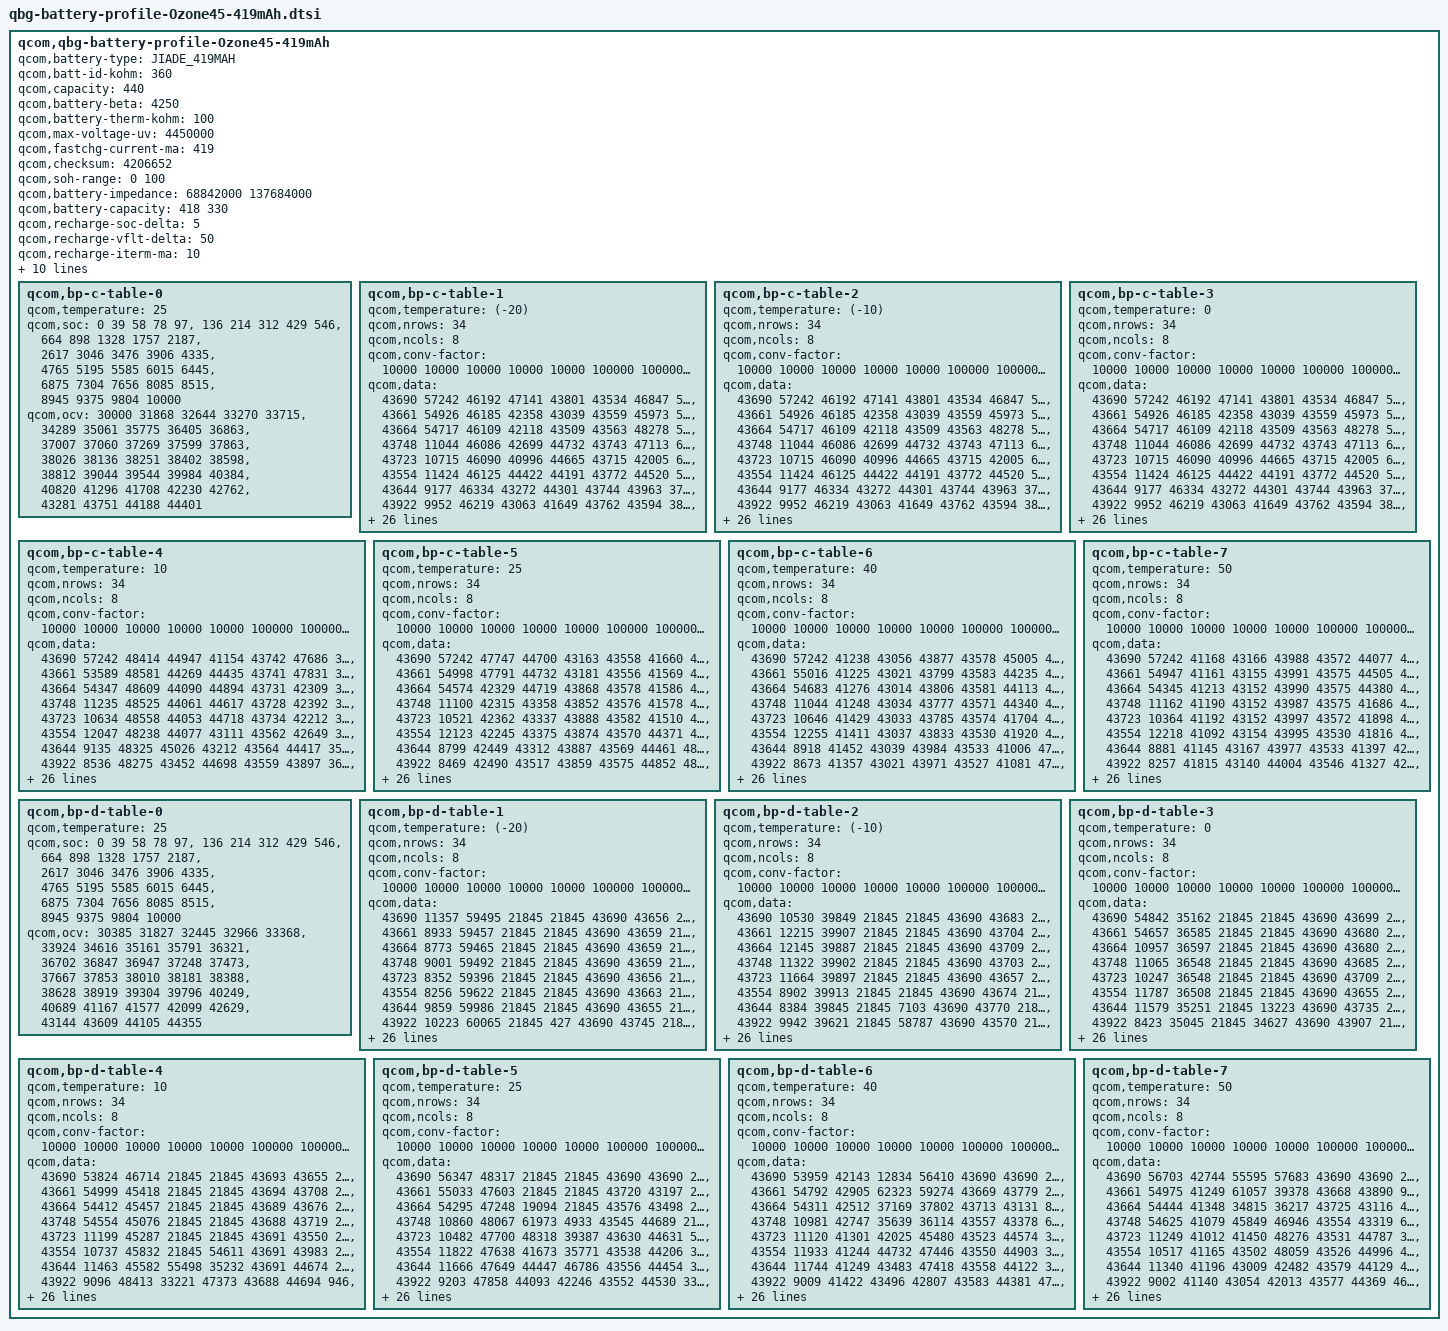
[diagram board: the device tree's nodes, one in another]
qcom,qbg-battery-profile-Ozone45-419mAh {
	qcom,battery-type = "JIADE_419MAH";
	qcom,batt-id-kohm = <360>;
	qcom,capacity = <440>;
	qcom,battery-beta = <4250>;
	qcom,battery-therm-kohm = <100>;
	qcom,max-voltage-uv = <4450000>;
	qcom,fastchg-current-ma = <419>;
	qcom,checksum = <4206652>; /*@5, 0.005V, 4% */
	qcom,soh-range = <0 100>;
	/* Nominal_Impedance in 10nohm @ SOC 50% 25C* 0:fresh cell, 1: aged cell */
	qcom,battery-impedance = <68842000 137684000>;
	/* Nominal_Capacity in mAh. 0: fresh cell, 1:aged cell */
	qcom,battery-capacity = <418 330>;
	/* SOC delta (in percent) dropped from EOC SOC to enable recharge */
	qcom,recharge-soc-delta =<5>;
	/* vfloat delta (in mV) dropped from regular vfloat in recharge */
	qcom,recharge-vflt-delta =<50>;
	/* Termination current (in mA) in recharge */
	qcom,recharge-iterm-ma = <10>;

	qcom,jeita-fcc-ranges = <0 150 84000
				151 435 419000
				436 445 400000
				446 450 84000>;

	qcom,jeita-fv-ranges = <0 150 4300000
				151 435 4450000
				436 445 4450000
				446 450 4350000>;

	/* COOL = 15 DegC, WARM = 45 DegC */
	qcom,jeita-soft-thresholds = <0x27c1 0x128c>;
	/* COLD = 0 DegC, HOT = 45.1 DegC */
	qcom,jeita-hard-thresholds = <0x3257 0x127e>;
	/* COOL = 18 DegC, WARM = 44 DegC*/
	qcom,jeita-soft-hys-thresholds = <0x256e 0x131c>;
	qcom,step-jeita-hysteresis = <5 5>;
	qcom,jeita-soft-fcc-ua = <140000 419000>;
	qcom,jeita-soft-fv-uv = <4300000 4300000>;

	qcom,bp-c-table-0 {
		qcom,temperature = <25>;
		qcom,soc = <    0    39    58    78    97>,
			<  136   214   312   429   546>,
			<  664   898  1328  1757  2187>,
			< 2617  3046  3476  3906  4335>,
			< 4765  5195  5585  6015  6445>,
			< 6875  7304  7656  8085  8515>,
			< 8945  9375  9804 10000>;
		qcom,ocv = <30000 31868 32644 33270 33715>,
			<34289 35061 35775 36405 36863>,
			<37007 37060 37269 37599 37863>,
			<38026 38136 38251 38402 38598>,
			<38812 39044 39544 39984 40384>,
			<40820 41296 41708 42230 42762>,
			<43281 43751 44188 44401>;
	};
	qcom,bp-c-table-1 {
		qcom,temperature = <(-20)>;
		qcom,nrows = <34>;
		qcom,ncols = <8>;
		qcom,conv-factor = <10000 10000 10000 10000 10000 100000 100000 10000>;
		qcom,data = <43690 57242 46192 47141 43801 43534 46847 59275>,
			<43661 54926 46185 42358 43039 43559 45973 57509>,
			<43664 54717 46109 42118 43509 43563 48278 58074>,
			<43748 11044 46086 42699 44732 43743 47113 60539>,
			<43723 10715 46090 40996 44665 43715 42005 61329>,
			<43554 11424 46125 44422 44191 43772 44520 59646>,
			<43644  9177 46334 43272 44301 43744 43963 37901>,
			<43922  9952 46219 43063 41649 43762 43594 38406>,
			<43783  9325 46237 43145 41622 43722 43586 37319>,
			<43144 15049 46220 43245 44306 43716 43600 37107>,
			<43058 14926 46969 43813 41528 43724 43622 37707>,
			<43304 15232 46859 44320 43421 43564 44897 37724>,
			<44954 14519 46958 41799 44796 43733 41832 38575>,
			<44151 14811 47058 41019 44803 43560 41186 38653>,
			<41505 16094 47049 41398 44070 43561 40968 38405>,
			<41107 16304 46985 41249 44464 43561 41098 38510>,
			<41292 16351 47012 41343 44302 43563 41731 38482>,
			<42814 16250 46659 42679 41638 43562 41767 38834>,
			<42472 15511 46671 42700 41480 43733 41782 38672>,
			<47685 15467 46694 42599 41876 43732 41023 37938>,
			<47159 15662 46621 42987 41919 43735 42515 38102>,
			<48865 12903 46624 42955 44481 43730 42555 38413>,
			<49019 12439 46786 42976 44256 43737 41846 36946>,
			<48597 12570 46797 42919 44041 43739 44910 36982>,
			<45959 14270 46841 42807 44499 43717 44187 38564>,
			<45169 13437 46741 42854 44424 43716 45046 37190>,
			<46626  2618 46820 42224 44312 43716 44969 38830>,
			<46914  2235 46642 41987 41880 43719 44692 38366>,
			<46399  3754 47080 42069 42709 43716 43421 61053>,
			<35817  3925 46957 42454 47727 43738 43031 59045>,
			<34907   672 46120 42341 48566 43736 43233 65379>,
			<36405   170 46513 42243 35534 43737 43171 51241>,
			<36070  1706 46545 41641 36022 43934 43953 53242>,
			<36282  1560 46419 42930 48907 43559 43827 63200>;
	};
	qcom,bp-c-table-2 {
		qcom,temperature = <(-10)>;
		qcom,nrows = <34>;
		qcom,ncols = <8>;
		qcom,conv-factor = <10000 10000 10000 10000 10000 100000 100000 10000>;
		qcom,data = <43690 57242 46192 47141 43801 43534 46847 59275>,
			<43661 54926 46185 42358 43039 43559 45973 57509>,
			<43664 54717 46109 42118 43509 43563 48278 58074>,
			<43748 11044 46086 42699 44732 43743 47113 60539>,
			<43723 10715 46090 40996 44665 43715 42005 61329>,
			<43554 11424 46125 44422 44191 43772 44520 59646>,
			<43644  9177 46334 43272 44301 43744 43963 37901>,
			<43922  9952 46219 43063 41649 43762 43594 38406>,
			<43783  9325 46237 43145 41622 43722 43586 37319>,
			<43144 15049 46220 43245 44306 43716 43600 37107>,
			<43058 14926 46969 43813 41528 43724 43622 37707>,
			<43304 15232 46859 44320 43421 43564 44897 37724>,
			<44954 14519 46958 41799 44796 43733 41832 38575>,
			<44151 14811 47058 41019 44803 43560 41186 38653>,
			<41505 16094 47049 41398 44070 43561 40968 38405>,
			<41107 16304 46985 41249 44464 43561 41098 38510>,
			<41292 16351 47012 41343 44302 43563 41731 38482>,
			<42814 16250 46659 42679 41638 43562 41767 38834>,
			<42472 15511 46671 42700 41480 43733 41782 38672>,
			<47685 15467 46694 42599 41876 43732 41023 37938>,
			<47159 15662 46621 42987 41919 43735 42515 38102>,
			<48865 12903 46624 42955 44481 43730 42555 38413>,
			<49019 12439 46786 42976 44256 43737 41846 36946>,
			<48597 12570 46797 42919 44041 43739 44910 36982>,
			<45959 14270 46841 42807 44499 43717 44187 38564>,
			<45169 13437 46741 42854 44424 43716 45046 37190>,
			<46626  2618 46820 42224 44312 43716 44969 38830>,
			<46914  2235 46642 41987 41880 43719 44692 38366>,
			<46399  3754 47080 42069 42709 43716 43421 61053>,
			<35817  3925 46957 42454 47727 43738 43031 59045>,
			<34907   672 46120 42341 48566 43736 43233 65379>,
			<36405   170 46513 42243 35534 43737 43171 51241>,
			<36070  1706 46545 41641 36022 43934 43953 53242>,
			<36282  1560 46419 42930 48907 43559 43827 63200>;
	};
	qcom,bp-c-table-3 {
		qcom,temperature = <0>;
		qcom,nrows = <34>;
		qcom,ncols = <8>;
		qcom,conv-factor = <10000 10000 10000 10000 10000 100000 100000 10000>;
		qcom,data = <43690 57242 46192 47141 43801 43534 46847 59275>,
			<43661 54926 46185 42358 43039 43559 45973 57509>,
			<43664 54717 46109 42118 43509 43563 48278 58074>,
			<43748 11044 46086 42699 44732 43743 47113 60539>,
			<43723 10715 46090 40996 44665 43715 42005 61329>,
			<43554 11424 46125 44422 44191 43772 44520 59646>,
			<43644  9177 46334 43272 44301 43744 43963 37901>,
			<43922  9952 46219 43063 41649 43762 43594 38406>,
			<43783  9325 46237 43145 41622 43722 43586 37319>,
			<43144 15049 46220 43245 44306 43716 43600 37107>,
			<43058 14926 46969 43813 41528 43724 43622 37707>,
			<43304 15232 46859 44320 43421 43564 44897 37724>,
			<44954 14519 46958 41799 44796 43733 41832 38575>,
			<44151 14811 47058 41019 44803 43560 41186 38653>,
			<41505 16094 47049 41398 44070 43561 40968 38405>,
			<41107 16304 46985 41249 44464 43561 41098 38510>,
			<41292 16351 47012 41343 44302 43563 41731 38482>,
			<42814 16250 46659 42679 41638 43562 41767 38834>,
			<42472 15511 46671 42700 41480 43733 41782 38672>,
			<47685 15467 46694 42599 41876 43732 41023 37938>,
			<47159 15662 46621 42987 41919 43735 42515 38102>,
			<48865 12903 46624 42955 44481 43730 42555 38413>,
			<49019 12439 46786 42976 44256 43737 41846 36946>,
			<48597 12570 46797 42919 44041 43739 44910 36982>,
			<45959 14270 46841 42807 44499 43717 44187 38564>,
			<45169 13437 46741 42854 44424 43716 45046 37190>,
			<46626  2618 46820 42224 44312 43716 44969 38830>,
			<46914  2235 46642 41987 41880 43719 44692 38366>,
			<46399  3754 47080 42069 42709 43716 43421 61053>,
			<35817  3925 46957 42454 47727 43738 43031 59045>,
			<34907   672 46120 42341 48566 43736 43233 65379>,
			<36405   170 46513 42243 35534 43737 43171 51241>,
			<36070  1706 46545 41641 36022 43934 43953 53242>,
			<36282  1560 46419 42930 48907 43559 43827 63200>;
	};
	qcom,bp-c-table-4 {
		qcom,temperature = <10>;
		qcom,nrows = <34>;
		qcom,ncols = <8>;
		qcom,conv-factor = <10000 10000 10000 10000 10000 100000 100000 10000>;
		qcom,data = <43690 57242 48414 44947 41154 43742 47686 39881>,
			<43661 53589 48581 44269 44435 43741 47831 34232>,
			<43664 54347 48609 44090 44894 43731 42309 34633>,
			<43748 11235 48525 44061 44617 43728 42392 34333>,
			<43723 10634 48558 44053 44718 43734 42212 33087>,
			<43554 12047 48238 44077 43111 43562 42649 33582>,
			<43644  9135 48325 45026 43212 43564 44417 35951>,
			<43922  8536 48275 43452 44698 43559 43897 36854>,
			<43783  9413 48299 44736 43130 43578 44755 36471>,
			<43144 15002 49004 43310 43511 43570 43026 35181>,
			<43058 14875 48922 43498 43264 43568 43862 35115>,
			<43304 14912 48924 45020 43145 43583 41507 35175>,
			<44954 15201 48942 44071 43313 43578 41095 36801>,
			<44151 14775 49126 44098 44549 43576 41126 36011>,
			<41505 16013 49048 44438 45036 43577 41109 36084>,
			<41107 15980 49069 44340 44844 43576 41011 35877>,
			<41292 16258 48738 44363 44826 43578 41163 35850>,
			<42814 16190 48692 41641 44912 43557 41926 35848>,
			<42472 15541 48688 41638 44177 43559 44397 35967>,
			<47685 15466 48849 41646 44459 43558 44119 36336>,
			<47159 15839 48880 41718 44368 43559 41697 33496>,
			<48865 12998 48890 41890 44365 43582 42868 33378>,
			<49019 12430 48784 41483 44860 43558 41252 36698>,
			<48597 13996 48807 41615 44583 43567 44090 36591>,
			<45959 14138 48810 41694 44550 43557 44903 36409>,
			<45169 13792 48827 41869 44724 43572 44128 36442>,
			<46626  2976 48806 41544 44992 43732 44660 36673>,
			<46914  2098 48805 41939 44806 43735 44638 35915>,
			<46399  3638 48772 41802 44237 43734 44767 33481>,
			<35817  3079 48837 40991 41725 43729 43372 33120>,
			<34907   541 48754 41039 41282 43732 43396 39498>,
			<36405    60 49147 41002 47207 43561 43010 37403>,
			<36070  1742 48902 44471 48084 43576 43171 40073>,
			<36282  1926 48984 44560 47887 43737 43907 40559>;
	};
	qcom,bp-c-table-5 {
		qcom,temperature = <25>;
		qcom,nrows = <34>;
		qcom,ncols = <8>;
		qcom,conv-factor = <10000 10000 10000 10000 10000 100000 100000 10000>;
		qcom,data = <43690 57242 47747 44700 43163 43558 41660 46054>,
			<43661 54998 47791 44732 43181 43556 41569 45691>,
			<43664 54574 42329 44719 43868 43578 41586 45627>,
			<43748 11100 42315 43358 43852 43576 41578 45817>,
			<43723 10521 42362 43337 43888 43582 41510 45756>,
			<43554 12123 42245 43375 43874 43570 44371 48397>,
			<43644  8799 42449 43312 43887 43569 44461 48572>,
			<43922  8469 42490 43517 43859 43575 44852 48147>,
			<43783  9375 42379 43416 43195 43533 45000 48331>,
			<43144  9557 42073 43442 43891 43522 44062 48992>,
			<43058 14885 42061 43408 43986 43528 41948 49089>,
			<43304 14958 42109 43472 43863 43522 41973 48295>,
			<44954 15167 42013 43356 43320 43521 44341 48502>,
			<44151 14453 42042 44675 44694 43524 44360 45778>,
			<41505 14669 42177 44784 44747 43521 41513 45579>,
			<41107 15904 42233 44583 44777 43532 41780 45605>,
			<41292 15954 42129 44641 44683 43528 41829 45601>,
			<42814 16321 42160 44931 44727 43531 41862 45673>,
			<42472 15528 42839 45029 44796 43529 44527 46002>,
			<47685 15468 42831 44607 44854 43529 44793 46030>,
			<47159 15670 42771 44780 44135 43568 44767 45193>,
			<48865 12846 42806 44945 44423 43530 41758 45567>,
			<49019 12498 42797 44558 43336 43574 44122 48632>,
			<48597 13978 42956 44592 43406 43571 44925 48321>,
			<45959 14186 42999 44640 43417 43570 45007 48179>,
			<45169 13790 43001 44975 43484 43581 44620 48561>,
			<46626  3066 42983 44946 43337 43580 44797 48407>,
			<46914  2118 43003 44993 44794 43577 44729 45761>,
			<46399  3676 43002 44878 44560 43576 44686 46026>,
			<35817  3488 42953 44254 44952 43576 44788 45101>,
			<34907   955 42784 44448 44124 43577 43363 46984>,
			<36405    77 42849 44053 41455 43575 43427 35787>,
			<36070  1590 42126 44669 41192 43571 43074 46162>,
			<36282  2011 42117 43500 41461 43572 43828 46130>;
	};
	qcom,bp-c-table-6 {
		qcom,temperature = <40>;
		qcom,nrows = <34>;
		qcom,ncols = <8>;
		qcom,conv-factor = <10000 10000 10000 10000 10000 100000 100000 10000>;
		qcom,data = <43690 57242 41238 43056 43877 43578 45005 48016>,
			<43661 55016 41225 43021 43799 43583 44235 48039>,
			<43664 54683 41276 43014 43806 43581 44113 47709>,
			<43748 11044 41248 43034 43777 43571 44340 47688>,
			<43723 10646 41429 43033 43785 43574 41704 47719>,
			<43554 12255 41411 43037 43833 43530 41920 47630>,
			<43644  8918 41452 43039 43984 43533 41006 47856>,
			<43922  8673 41357 43021 43971 43527 41081 47807>,
			<43783 10094 41403 43065 43973 43544 41132 42306>,
			<43144  9527 41047 43159 43991 43630 41684 42281>,
			<43058 15099 41050 43894 44003 43629 41945 42103>,
			<43304 14892 41027 43861 43848 43631 44185 42301>,
			<44954 15341 41073 43238 43090 43618 44933 47711>,
			<44151 14370 41059 43214 43417 43617 44876 48029>,
			<41505 14806 40981 43051 43506 43618 44456 48091>,
			<41107 16026 40986 43049 43428 43627 41645 48056>,
			<41292 15891 41014 43062 43062 43539 41512 47719>,
			<42814 16279 40992 43103 43064 43544 41651 48046>,
			<42472 16203 41170 43501 43131 43524 44262 47935>,
			<47685 15361 41167 43311 43512 43536 44944 47358>,
			<47159 15626 41210 43029 44660 43624 43444 47199>,
			<48865 12821 41194 43143 44204 43525 43323 47555>,
			<49019 12344 41089 43041 43068 43547 44063 47852>,
			<48597 13970 41103 43226 43186 43547 44854 42294>,
			<45959 14203 41137 43228 43232 43525 44763 42362>,
			<45169 13601 41148 43027 43067 43521 44584 47818>,
			<46626  3009 41144 43435 43086 43523 44753 47701>,
			<46914  2465 41125 43411 43396 43520 44751 47907>,
			<46399  4028 41148 43273 43485 43525 44644 47353>,
			<35817  3459 41140 43368 44713 43521 44786 47526>,
			<34907   910 41095 44770 44769 43545 44638 47424>,
			<36405    88 41108 44768 44249 43549 43338 48286>,
			<36070  1536 41166 43080 44853 43544 43492 47448>,
			<36282  1831 41197 43845 44360 43535 43880 49036>;
	};
	qcom,bp-c-table-7 {
		qcom,temperature = <50>;
		qcom,nrows = <34>;
		qcom,ncols = <8>;
		qcom,conv-factor = <10000 10000 10000 10000 10000 100000 100000 10000>;
		qcom,data = <43690 57242 41168 43166 43988 43572 44077 42384>,
			<43661 54947 41161 43155 43991 43575 44505 42430>,
			<43664 54345 41213 43152 43990 43575 44380 42408>,
			<43748 11162 41190 43152 43987 43575 41686 42074>,
			<43723 10364 41192 43152 43997 43572 41898 42100>,
			<43554 12218 41092 43154 43995 43530 41816 42007>,
			<43644  8881 41145 43167 43977 43533 41397 42031>,
			<43922  8257 41815 43140 44004 43546 41327 42209>,
			<43783 10191 41795 43150 44015 43551 41294 42166>,
			<43144  9707 41843 43182 43928 43619 41281 42872>,
			<43058 15039 41848 44001 43934 43598 44442 42927>,
			<43304 15085 41825 43788 43785 43646 44273 42866>,
			<44954 14935 41839 43178 43209 43641 44882 42055>,
			<44151 14568 41750 43853 43070 43634 44924 42068>,
			<41505 14750 41752 43843 43129 43633 44222 42396>,
			<41107 14675 41741 43890 43070 43647 44097 42104>,
			<41292 15922 41779 43848 43188 43628 44300 42024>,
			<42814 16256 41760 43162 43194 43538 44326 41984>,
			<42472 16252 41942 43049 43257 43546 44172 42469>,
			<47685 15362 41946 43027 43116 43544 44656 42327>,
			<47159 15627 41929 43032 43320 43631 43279 47630>,
			<48865 12920 41976 43782 44966 43642 43061 48040>,
			<49019 12339 41964 43852 43247 43628 44457 42226>,
			<48597 13972 41878 43850 43779 43626 44237 42755>,
			<45959 14193 41884 43841 43888 43543 45034 42828>,
			<45169 13622 41882 43860 43246 43539 44796 42186>,
			<46626  3028 41857 43240 43041 43545 44594 42076>,
			<46914  2486 41859 43054 43115 43546 44620 42460>,
			<46399  3971 41858 43013 43446 43544 44571 47788>,
			<35817  3486 41863 43439 43505 43548 44958 47618>,
			<34907   900 41886 43429 43360 43545 44566 48003>,
			<36405    88 41873 43485 44623 43626 44555 47125>,
			<36070  1540 41978 43246 44793 43539 43312 47682>,
			<36282  1842 41867 43148 44957 43538 43261 48067>;
	};
	qcom,bp-d-table-0 {
		qcom,temperature = <25>;
		qcom,soc = <    0    39    58    78    97>,
			<  136   214   312   429   546>,
			<  664   898  1328  1757  2187>,
			< 2617  3046  3476  3906  4335>,
			< 4765  5195  5585  6015  6445>,
			< 6875  7304  7656  8085  8515>,
			< 8945  9375  9804 10000>;
		qcom,ocv = <30385 31827 32445 32966 33368>,
			<33924 34616 35161 35791 36321>,
			<36702 36847 36947 37248 37473>,
			<37667 37853 38010 38181 38388>,
			<38628 38919 39304 39796 40249>,
			<40689 41167 41577 42099 42629>,
			<43144 43609 44105 44355>;
	};
	qcom,bp-d-table-1 {
		qcom,temperature = <(-20)>;
		qcom,nrows = <34>;
		qcom,ncols = <8>;
		qcom,conv-factor = <10000 10000 10000 10000 10000 100000 100000 10000>;
		qcom,data = <43690 11357 59495 21845 21845 43690 43656 21845>,
			<43661  8933 59457 21845 21845 43690 43659 21845>,
			<43664  8773 59465 21845 21845 43690 43659 21845>,
			<43748  9001 59492 21845 21845 43690 43659 21845>,
			<43723  8352 59396 21845 21845 43690 43656 21845>,
			<43554  8256 59622 21845 21845 43690 43663 21845>,
			<43644  9859 59986 21845 21845 43690 43655 21845>,
			<43922 10223 60065 21845   427 43690 43745 21845>,
			<43783  9393 60385 21845 52701 43690 43729 21845>,
			<43144  9218 37897 21845 57870 43690 43533 21845>,
			<43058  9660 38474 21845 40181 43690 43646 21845>,
			<43304  9580 36882 21845 35153 43690 43928 21845>,
			<44954 14860 37786 31899 46483 43691 43836 21845>,
			<44151 15350 40375 12672 45552 43691 43845 21845>,
			<41505 15184 40711 53677 48617 43691 43146 21845>,
			<41107 14373 40818 49563 48916 43688 43178 21845>,
			<41292 14733 40727 62700 48647 43688 43870 21845>,
			<42814 14613 40744 63572 48769 43688 43894 21845>,
			<42472 16124 40706 57954 47450 43688 43875 21845>,
			<47685 15940 40775 38144 47443 43688 43795 21845>,
			<47159 16166 40094 40278 48794 43688 43789 21845>,
			<48865 15592 40161 39102 48876 43688 43789 21845>,
			<49019 15794 40129 33895 48769 43688 43851 21883>,
			<48597 13012 40145 34751 48361 43688 43064 21554>,
			<45959 12416 40818 34436 45950 43688 43118 21803>,
			<45169 13850 40780 39725 35723 43689 44912 21845>,
			<46626 13778 40106 38991 33922 43694 44238 21845>,
			<46914  2988 40775 39626 39418 43694 44725 21845>,
			<46399  2238 40124 34059 33117 43695 43035 21845>,
			<35817  3641 40759 39805 33186 43650 43358 21845>,
			<34907  3124 40100 40420 34578 43693 43434 21845>,
			<36405   581 40160 38680 32995 43689 43165 21845>,
			<36070   332 40084 60958 35504 43689 43793 21845>,
			<36282  1838 40780 60751 45464 43694 43792 21845>;
	};
	qcom,bp-d-table-2 {
		qcom,temperature = <(-10)>;
		qcom,nrows = <34>;
		qcom,ncols = <8>;
		qcom,conv-factor = <10000 10000 10000 10000 10000 100000 100000 10000>;
		qcom,data = <43690 10530 39849 21845 21845 43690 43683 21845>,
			<43661 12215 39907 21845 21845 43690 43704 21845>,
			<43664 12145 39887 21845 21845 43690 43709 21845>,
			<43748 11322 39902 21845 21845 43690 43703 21845>,
			<43723 11664 39897 21845 21845 43690 43657 21845>,
			<43554  8902 39913 21845 21845 43690 43674 21845>,
			<43644  8384 39845 21845  7103 43690 43770 21845>,
			<43922  9942 39621 21845 58787 43690 43570 21845>,
			<43783  9352 34209 21845 34462 43690 43925 21845>,
			<43144  9336 34815 21845 46677 43690 43786 21845>,
			<43058  9604 34502 26631 48657 43691 43855 21845>,
			<43304  9500 33250 54844 42214 43691 43159 21845>,
			<44954 14863 32888 63213 42169 43691 43140 21845>,
			<44151 15323 32805 64116 42405 43688 43202 21845>,
			<41505 14477 32967 59910 42053 43688 43228 16463>,
			<41107 14436 32956 39835 42020 43688 43227 32622>,
			<41292 14796 32865 36750 42218 43688 43263 26915>,
			<42814 14683 32804 46680 42875 43689 43163  7710>,
			<42472 16094 32930 48594 42956 43694 43171   720>,
			<47685 15956 32915 47370 42941 43692 43865 14144>,
			<47159 16147 32865 47889 42597 43684 43232 15625>,
			<48865 15789 32905 47944 42845 43666 44962 15749>,
			<49019 12837 32977 47152 47274 43726 44280 13080>,
			<48597 12437 32914 47467 49027 43718 44908 12295>,
			<45959 14065 33007 48187 45420 43718 44077  2629>,
			<45169 13531 32794 48967 36430 43725 44614  3276>,
			<46626  2783 32793 45979 36396 43712 44791   993>,
			<46914  2226 33009 46554 35503 43739 44814    49>,
			<46399  2374 33021 46769 34873 43763 43353   206>,
			<35817  3260 32972 46871 35108 43764 44692  1516>,
			<34907   699 32971 46931 35107 43767 43331  7073>,
			<36405   840 32768 46889 46921 43774 43460  1423>,
			<36070  1694 33251 46846 47243 43758 43126   968>,
			<36282  1838 33033 45388 42342 43669 43070  3134>;
	};
	qcom,bp-d-table-3 {
		qcom,temperature = <0>;
		qcom,nrows = <34>;
		qcom,ncols = <8>;
		qcom,conv-factor = <10000 10000 10000 10000 10000 100000 100000 10000>;
		qcom,data = <43690 54842 35162 21845 21845 43690 43699 21845>,
			<43661 54657 36585 21845 21845 43690 43680 21845>,
			<43664 10957 36597 21845 21845 43690 43680 21845>,
			<43748 11065 36548 21845 21845 43690 43685 21845>,
			<43723 10247 36548 21845 21845 43690 43709 21845>,
			<43554 11787 36508 21845 21845 43690 43655 21845>,
			<43644 11579 35251 21845 13223 43690 43735 21845>,
			<43922  8423 35045 21845 34627 43690 43907 21845>,
			<43783  9851 35354 12855 47944 43691 43256 21845>,
			<43144  9426 35460 61555 47815 43691 43058 21608>,
			<43058  9648 35512 59944 42228 43691 43010 32547>,
			<43304  9530 46450 36021 41404 43688 43231   164>,
			<44954 15064 35470 48771 41732 43694 43217 12270>,
			<44151 15112 46536 47986 41313 43693 43471 54796>,
			<41505 14391 46535 42764 41268 43754 44806 50518>,
			<41107 14744 46470 41260 41096 43725 44918 51225>,
			<41292 14655 46487 41022 44365 43717 44960 64816>,
			<42814 14687 46385 41977 44455 43712 43338 58703>,
			<42472 16087 46356 41476 44541 43766 43279 57681>,
			<47685 16327 46503 41005 44293 43741 44438 57741>,
			<47159 15405 46522 41033 41126 43735 44049 57729>,
			<48865 15712 46584 41257 41289 43562 44284 59112>,
			<49019 13239 46498 42661 42858 43562 44898 59383>,
			<48597 12319 46203 42570 42392 43733 44944 58378>,
			<45959 13929 46194 42982 49027 43733 44768 65056>,
			<45169 13424 46103 42399 48174 43734 44712 64873>,
			<46626  2670 46081 47727 48759 43743 44715 64884>,
			<46914  2249 46198 42353 49003 43736 43473 62175>,
			<46399  3785 46110 47762 49039 43738 43485 62446>,
			<35817  3289 46172 47671 49132 43738 43325 61900>,
			<34907   732 46200 47652 48929 43738 43266 63381>,
			<36405   149 46168 47785 47215 43738 43264 63224>,
			<36070  1778 46535 42074 42747 43719 43316 62185>,
			<36282  2000 46443 41994 41039 43718 43302 65331>;
	};
	qcom,bp-d-table-4 {
		qcom,temperature = <10>;
		qcom,nrows = <34>;
		qcom,ncols = <8>;
		qcom,conv-factor = <10000 10000 10000 10000 10000 100000 100000 10000>;
		qcom,data = <43690 53824 46714 21845 21845 43693 43655 21845>,
			<43661 54999 45418 21845 21845 43694 43708 21845>,
			<43664 54412 45457 21845 21845 43689 43676 21845>,
			<43748 54554 45076 21845 21845 43688 43719 21845>,
			<43723 11199 45287 21845 21845 43691 43550 21845>,
			<43554 10737 45832 21845 54611 43691 43983 21845>,
			<43644 11463 45582 55498 35232 43691 44674 21845>,
			<43922  9096 48413 33221 47373 43688 44694   946>,
			<43783  8570 48411 48965 42131 43693 43347 56580>,
			<43144 10066 48585 42151 42743 43709 43390 52213>,
			<43058  9628 48516 41275 42664 43673 43389 64928>,
			<43304  9571 48527 41858 41651 43769 44789 61248>,
			<44954 15055 48252 44534 44815 43712 44973 40364>,
			<44151 15119 48181 44295 44495 43740 44992 40105>,
			<41505 14396 48160 44507 44345 43560 44204 39778>,
			<41107 14723 48361 44479 44077 43554 44236 34584>,
			<41292 14645 48283 44149 44815 43552 44462 32859>,
			<42814 16005 48305 44159 44902 43552 44533 32896>,
			<42472 15955 48966 44121 44123 43558 44142 32814>,
			<47685 16230 48914 44460 44135 43579 44163 33728>,
			<47159 15459 48953 44420 44158 43578 44876 33375>,
			<48865 15699 49112 44510 44526 43556 44816 33695>,
			<49019 13306 49143 44366 41684 43556 44852 32831>,
			<48597 12674 49134 41596 41254 43557 44807 34013>,
			<45959 14209 49053 41795 42119 43558 44609 39146>,
			<45169 13757 49134 41122 42190 43566 43478 38934>,
			<46626  2649 49092 41750 42560 43733 43453 39875>,
			<46914  2085 49109 41797 41233 43734 43430 39514>,
			<46399  3635 48957 41112 40988 43729 43483 39542>,
			<35817  3079 48900 41113 40988 43734 43361 39739>,
			<34907   517 48966 41132 41368 43733 43357 39332>,
			<36405   221 48309 41767 41183 43566 44700 39004>,
			<36070  1735 48273 41577 41660 43555 44581 39509>,
			<36282  2010 48279 41667 44474 43558 44560 34209>;
	};
	qcom,bp-d-table-5 {
		qcom,temperature = <25>;
		qcom,nrows = <34>;
		qcom,ncols = <8>;
		qcom,conv-factor = <10000 10000 10000 10000 10000 100000 100000 10000>;
		qcom,data = <43690 56347 48317 21845 21845 43690 43690 21845>,
			<43661 55033 47603 21845 21845 43720 43197 21845>,
			<43664 54295 47248 19094 21845 43576 43498 21845>,
			<43748 10860 48067 61973  4933 43545 44689 21845>,
			<43723 10482 47700 48318 39387 43630 44631 52106>,
			<43554 11822 47638 41673 35771 43538 44206 38242>,
			<43644 11666 47649 44447 46786 43556 44454 37805>,
			<43922  9203 47858 44093 42246 43552 44530 33275>,
			<43783  8549 47753 44171 41883 43558 44526 35172>,
			<43144 10059 42304 45028 44200 43559 44817 46527>,
			<43058  9716 42338 44992 44133 43577 44793 46388>,
			<43304  9541 42249 44747 44657 43579 44720 46764>,
			<44954 15097 42456 43273 43449 43583 45010 45593>,
			<44151 15146 42490 43336 44722 43572 44978 45872>,
			<41505 14539 42420 43385 44700 43535 44197 45955>,
			<41107 14729 42411 43341 45022 43523 44106 45215>,
			<41292 14711 42101 44711 44133 43524 44032 45532>,
			<42814 16080 42009 44709 44087 43525 44998 45121>,
			<42472 16271 42024 44713 44862 43526 44630 45870>,
			<47685 16222 42231 44709 44657 43521 44971 45577>,
			<47159 15438 42239 44728 44768 43532 44963 48456>,
			<48865 12973 42168 44677 44769 43528 44930 48497>,
			<49019 13090 42833 44660 44056 43528 44898 45168>,
			<48597 12766 42824 45015 41098 43529 44551 46150>,
			<45959 14227 42868 45012 41130 43530 43089 46180>,
			<45169 13403 42868 44832 44382 43571 43013 46664>,
			<46626  2661 42870 44855 44246 43582 43105 45524>,
			<46914  2243 42818 45041 44910 43579 43112 45112>,
			<46399  3801 42155 45006 44613 43578 43493 45917>,
			<35817  3119 42166 45035 44579 43578 43289 45863>,
			<34907   546 42216 44973 44740 43579 44719 46025>,
			<36405   243 42176 44560 44739 43581 44789 46056>,
			<36070  1763 42042 44789 44754 43528 44650 45967>,
			<36282  2025 41995 44691 44589 43532 44657 46003>;
	};
	qcom,bp-d-table-6 {
		qcom,temperature = <40>;
		qcom,nrows = <34>;
		qcom,ncols = <8>;
		qcom,conv-factor = <10000 10000 10000 10000 10000 100000 100000 10000>;
		qcom,data = <43690 53959 42143 12834 56410 43690 43690 21845>,
			<43661 54792 42905 62323 59274 43669 43779 26737>,
			<43664 54311 42512 37169 37802 43713 43131  8690>,
			<43748 10981 42747 35639 36114 43557 43378 61706>,
			<43723 11120 41301 42025 45480 43523 44574 37421>,
			<43554 11933 41244 44732 47446 43550 44903 36740>,
			<43644 11744 41249 43483 47418 43558 44122 35092>,
			<43922  9009 41422 43496 42807 43583 44381 47089>,
			<43783  8545 41449 43446 44910 43575 41630 49038>,
			<43144 10103 41348 43101 43415 43535 44364 47355>,
			<43058  9720 41395 43445 43287 43526 45022 47195>,
			<43304  9588 41401 43064 43120 43546 44743 48071>,
			<44954 15003 41390 43896 43179 43626 44851 42241>,
			<44151 15358 41049 43170 43027 43626 44960 47654>,
			<41505 14494 41084 43858 43452 43625 44985 47645>,
			<41107 14752 41058 43170 43336 43623 44945 47916>,
			<41292 14662 40988 43158 45037 43644 44562 47523>,
			<42814 15887 41015 43232 44835 43633 44783 47586>,
			<42472 16359 41000 43163 44785 43647 43333 47948>,
			<47685 15551 41180 43146 43460 43628 43338 47730>,
			<47159 15790 41201 43244 43114 43543 44630 47764>,
			<48865 12937 41188 43242 43133 43538 44989 47853>,
			<49019 13152 41108 43427 44271 43642 44624 48698>,
			<48597 12598 41117 43317 44159 43616 43295 48998>,
			<45959 14306 41115 43313 44896 43548 43085 48746>,
			<45169 13396 41092 43485 44578 43522 43091 47615>,
			<46626  2678 41093 43487 43313 43528 43299 47320>,
			<46914  2268 41118 43476 43436 43528 44778 47989>,
			<46399  3798 41110 43446 43024 43573 44678 48018>,
			<35817  3104 41184 43024 43071 43572 43368 47646>,
			<34907   546 41207 43227 43217 43532 43336 47866>,
			<36405   243 41153 43159 43220 43525 44686 47754>,
			<36070  1761 41183 43189 43061 43551 44591 47798>,
			<36282  2025 41180 43190 43039 43549 44549 47768>;
	};
	qcom,bp-d-table-7 {
		qcom,temperature = <50>;
		qcom,nrows = <34>;
		qcom,ncols = <8>;
		qcom,conv-factor = <10000 10000 10000 10000 10000 100000 100000 10000>;
		qcom,data = <43690 56703 42744 55595 57683 43690 43690 29716>,
			<43661 54975 41249 61057 39378 43668 43890  9228>,
			<43664 54444 41348 34815 36217 43725 43116 49810>,
			<43748 54625 41079 45849 46946 43554 43319 60814>,
			<43723 11249 41012 41450 48276 43531 44787 33802>,
			<43554 10517 41165 43502 48059 43526 44996 46403>,
			<43644 11340 41196 43009 42482 43579 44129 47091>,
			<43922  9002 41140 43054 42013 43577 44369 46847>,
			<43783  8493 41129 43208 44202 43575 41705 47610>,
			<43144 10023 41793 43260 43426 43522 41674 47747>,
			<43058  9637 41846 43209 43511 43527 44994 47663>,
			<43304  9472 41844 43842 43054 43536 44719 42380>,
			<44954  9558 41829 43992 43776 43644 44081 42752>,
			<44151 15286 41833 43987 43201 43634 44597 42177>,
			<41505 14510 41754 43827 43115 43637 44957 42106>,
			<41107 14452 41743 43818 43446 43593 44585 42411>,
			<41292 14719 41779 43839 44676 43598 44713 47758>,
			<42814 15885 41761 43805 44568 43596 43271 47639>,
			<42472 16379 41948 43780 43318 43596 43326 42277>,
			<47685 15498 41923 43895 43025 43634 44552 42107>,
			<47159 15780 41971 43790 43259 43643 44581 42121>,
			<48865 12935 41977 43776 43255 43616 44617 42139>,
			<49019 13180 41954 43218 44982 43640 44604 47950>,
			<48597 12552 41962 43097 45036 43617 43276 47317>,
			<45959 14305 41873 43074 44693 43540 43470 47911>,
			<45169 13737 41884 43082 43502 43551 43335 47655>,
			<46626  2676 41886 43129 43025 43526 44745 42364>,
			<46914  2271 41885 43209 43068 43532 43280 42478>,
			<46399  3792 41884 43259 43136 43529 44753 42093>,
			<35817  3117 41876 43150 43866 43522 44969 42228>,
			<34907   555 41967 43842 43854 43544 44982 42145>,
			<36405   251 41953 43779 43862 43626 44618 42828>,
			<36070  1768 41979 43974 43157 43642 44777 42871>,
			<36282  1939 41976 44026 43261 43644 44717 42818>;
	};
};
